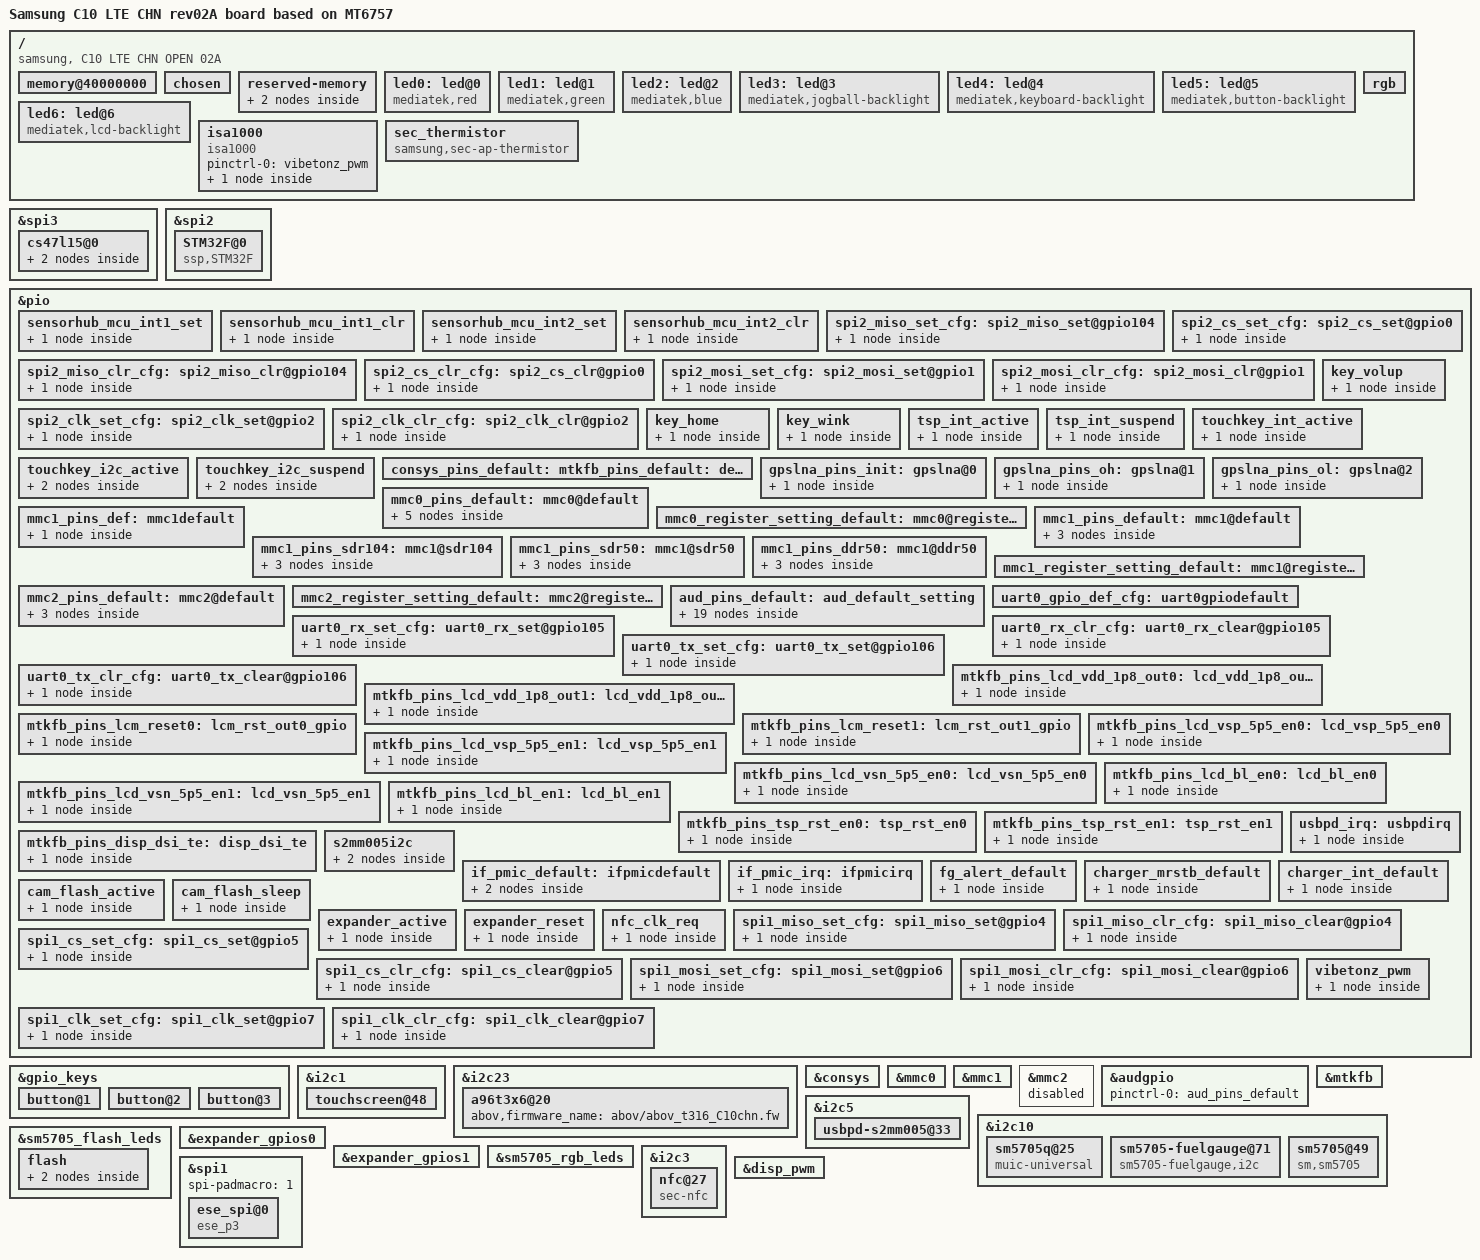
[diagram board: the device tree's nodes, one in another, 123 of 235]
/dts-v1/;

#include "mt6757.dtsi"
#include "mt6757_c10lte_chn_open_gpio_05.dtsi"
#include "mt6757_c10lte_fingerprint-sensor_00.dtsi"
#include <dt-bindings/input/input.h>
#include "battery_data_c10y17lte_common.dtsi"
#include "modem-MTK6757ap-pdata.dtsi"
#include "mt6757_camera_sensor_c10lte_chn_open_00.dtsi"
#include "mt6757_c10lte_sound.dtsi"
#include "mt6757_input_c10_common.dtsi"
#include "mtk-dsi-panel_s6e3fa3_ams549ku2x.dtsi"

/ {
	model = "Samsung C10 LTE CHN rev02A board based on MT6757";
	model_info-chip = <6757>;
	model_info-platform = "android";
	model_info-subtype = "mediatek";
	model_info-hw_rev = <5>;
	model_info-hw_rev_end = <5>;
	compatible = "samsung, C10 LTE CHN OPEN 02A", "mediatek,MT6757";

	memory@40000000 {
		device_type = "memory";
		reg = <0 0x40000000 0 0x1e605000>,
		      <1 0x00000000 0 0x20000000>;
	};

	/* chosen */
	chosen {
		bootargs = "console=tty0 console=ttyMT0,921600n1 root=/dev/ram initrd=0x45000000,
		0x1000000 loglevel=8 androidboot.selinux=permissive androidboot.hardware=mt6757";
		/* fpga may has no lk, we need to specify display info here */
		/* fb buffer is reserved using this dts by memory node above */
		atag,videolfb-fb_base_h = <0x0>;
		atag,videolfb-fb_base_l = <0x5e605000>;
		atag,videolfb-islcmfound = <1>;
		/* because no lk, so lcm is not inited */
		atag,videolfb-islcm_inited = <0>;
		atag,videolfb-fps= <6000>;
		atag,videolfb-vramSize= <0x017bb000>;
		atag,videolfb-dal_en= <0>;
		atag,videolfb-lcmname= "nt35695_fhd_dsi_cmd_truly_nt50358_drv";
	};

	reserved-memory {
		#address-cells = <2>;
		#size-cells = <2>;
		ranges;

		zone-movable-cma-memory {
			compatible = "mediatek,zone_movable_cma";
			size = <0 0x10000000>;
			/* 256MB alignment */
			alignment = <0 0x10000000>;
			alloc-ranges = <0 0xc0000000 1 0x00000000>;
		};

		dedicate-tui-memory {
			compatible = "mediatek,memory-tui";
			size = <0 0x2000000>;
			alignment = <0 0x400000>;
			alloc-ranges = <0 0x40000000 0 0x80000000>;
		};
	};

	led0:led@0 {
		compatible = "mediatek,red";
		led_mode = <0>;
		data = <1>;
		pwm_config = <0 0 0 0 0>;
	};
	led1:led@1 {
		compatible = "mediatek,green";
		led_mode = <0>;
		data = <1>;
		pwm_config = <0 0 0 0 0>;
	};
	led2:led@2 {
		compatible = "mediatek,blue";
		led_mode = <0>;
		data = <1>;
		pwm_config = <0 0 0 0 0>;
	};
	led3:led@3 {
		compatible = "mediatek,jogball-backlight";
		led_mode = <0>;
		data = <1>;
		pwm_config = <0 0 0 0 0>;
	};
	led4:led@4 {
		compatible = "mediatek,keyboard-backlight";
		led_mode = <0>;
		data = <1>;
		pwm_config = <0 0 0 0 0>;
	};
	led5:led@5 {
		compatible = "mediatek,button-backlight";
		led_mode = <0>;
		data = <1>;
		pwm_config = <0 0 0 0 0>;
	};
	led6:led@6 {
		compatible = "mediatek,lcd-backlight";
		led_mode = <4>;
		data = <1>;
		pwm_config = <3 0 0 0 0>;
	};

	/* VIBRATOR */
	isa1000:isa1000 {
		compatible = "isa1000";
	};

	/* start svc leds */
	rgb {
		device_type = <0>;
		rgb-name = "led_b", "led_g", "led_r";
		rgb-channel = <1 2 3>;

		normal_powermode_current = <255>;
		low_powermode_current = <51>;
		br_ratio_r = <26>;
		br_ratio_g = <5>;
		br_ratio_b = <49>;

		normal_powermode_current_bk = <255>;
		low_powermode_current_bk = <51>;
		br_ratio_r_bk = <26>;
		br_ratio_g_bk = <5>;
		br_ratio_b_bk = <49>;

		normal_powermode_current_gd = <255>;
		low_powermode_current_gd = <51>;
		br_ratio_r_gd = <11>;
		br_ratio_g_gd = <3>;
		br_ratio_b_gd = <55>;

		normal_powermode_current_wt = <255>;
		low_powermode_current_wt = <51>;
		br_ratio_r_wt = <18>;
		br_ratio_g_wt = <4>;
		br_ratio_b_wt = <42>;
	};
	/* end svc leds */

	sec_thermistor {
		compatible = "samsung,sec-ap-thermistor";
		status = "okay";
		adc_channel = <0>;
		adc_array = <65 88 109 133 163 199 240
                    254 262 270 280 288 300 316 325 338 367
                    380 399 412 426 439 452 464 489 521 547
                    560 570 578 616 643 675 708 735 763 790
                    952 1151 1389 1602 1934 2215 2664 2951 3428 3967
                    4502 4986>;

 		temp_array = <900 850 800 750 700 650 600        
					590 580 570 560 550 540 530 520 510 500
					490 480 470 460 450 440 430 420 410 400
					390 380 370 360 350 340 330 320 310 300
					250 200 150 100 50 0 (-50) (-100) (-150) (-200)
					(-250) (-300)>;
	};

	/delete-node/ accdet@;
};

/* audio device for each revision */
&spi3 {
	cs47l15@0 {
		cirrus,accdet {
			acc@1 {
				cirrus,micd-configs = <1 0 0xf 0 0>;
			};
		};
	};
};

/* Sensor Hub Start*/
&spi2 {
        #address-cells = <1>;
        #size-cells = <0>;
        status = "okay";

	STM32F@0 {
		compatible = "ssp,STM32F";
		reg = <0x00>;
		spi-max-frequency = <8000000>;

		interrupt-parent = <&eintc>;
		interrupts = <9 IRQ_TYPE_EDGE_FALLING>;

		pinctrl-names = "spi2_miso_set_cfg",
		"spi2_miso_clr_cfg",
		"spi2_cs_set_cfg",
		"spi2_cs_clr_cfg",
		"spi2_mosi_set_cfg",
		"spi2_mosi_clr_cfg",
		"spi2_clk_set_cfg",
		"spi2_clk_clr_cfg",
		"sensorhub_mcu_int1_set",
		"sensorhub_mcu_int1_clr",
		"sensorhub_mcu_int2_set",
		"sensorhub_mcu_int2_clr";
		pinctrl-0 = <&spi2_miso_set_cfg>;
		pinctrl-1 = <&spi2_miso_clr_cfg>;
		pinctrl-2 = <&spi2_cs_set_cfg>;
		pinctrl-3 = <&spi2_cs_clr_cfg>;
		pinctrl-4 = <&spi2_mosi_set_cfg>;
		pinctrl-5 = <&spi2_mosi_clr_cfg>;
		pinctrl-6 = <&spi2_clk_set_cfg>;
		pinctrl-7 = <&spi2_clk_clr_cfg>;

		pinctrl-8 = <&sensorhub_mcu_int1_set>;
		pinctrl-9 = <&sensorhub_mcu_int1_clr>;
		pinctrl-10 = <&sensorhub_mcu_int2_set>;
		pinctrl-11 = <&sensorhub_mcu_int2_clr>;

		gpio-controller;
		#gpio-cells = <2>;
		ssp,mcu_int1-gpio = <&pio 9 0>;
		ssp,mcu_int2-gpio = <&pio 115 0>;
		ssp,ap_int-gpio = <&expander_gpios1 4 0>;
		ssp,rst-gpio = <&expander_gpios1 3 0>;
		ssp,boot0-gpio = <&expander_gpios0 4 0>;
		ssp,acc-position = <3>;
		ssp,mag-position = <7>;
		ssp,prox-hi_thresh = <55>;
		ssp,prox-low_thresh = <40>;
		ssp,prox-detect_hi_thresh = <250>;
		ssp,prox-detect_low_thresh = <130>;
		ssp,mag-array = /bits/ 8 <0 0 0 0 0 0 0 0 0 0
					0 0 0 0 0 0 0 0 0 0
					0 0 0 0 0 0 0>;
		ssp,mag-type = <1>;
		ssp,acc-type = <1>;
		ssp,pressure-type = <1>;
		ssp,prox-type = <2>;
		/*ssp-sns-combination = <0>; where this is used*/
		/*ssp-ap-rev = <1>;*/
		
	};
};

&pio{
	sensorhub_mcu_int1_set: sensorhub_mcu_int1_set {
		pins_cmd_dat {
			pins = <PINMUX_GPIO9__FUNC_GPIO9>;
			slew-rate = <0>;	/* in */
			bias-disable;	/* no pull*/
		};
	};
	sensorhub_mcu_int1_clr: sensorhub_mcu_int1_clr {
		pins_cmd_dat {
			pins = <PINMUX_GPIO9__FUNC_GPIO9>;
			slew-rate = <0>;	/* in */
			bias-disable;	/* no pull*/
		};
	};
	sensorhub_mcu_int2_set: sensorhub_mcu_int2_set {
		pins_cmd_dat {
			pins = <PINMUX_GPIO115__FUNC_GPIO115>;
			slew-rate = <0>;	/* in */
			bias-disable;	/* no pull*/
		};
	};
	sensorhub_mcu_int2_clr: sensorhub_mcu_int2_clr {
		pins_cmd_dat {
			pins = <PINMUX_GPIO115__FUNC_GPIO115>;
			slew-rate = <0>;	/* in */
			bias-disable;	/* no pull*/
		};
	};  

	/* SPI2 GPIO SETTING */
	spi2_miso_set_cfg: spi2_miso_set@gpio104 {
		pins_cmd_dat {
			pins = <PINMUX_GPIO104__FUNC_SPI2_MI>;
		};
	};
	spi2_miso_clr_cfg: spi2_miso_clr@gpio104 {
		pins_cmd_dat {
			pins = <PINMUX_GPIO104__FUNC_GPIO104>;
			slew-rate = <0>;
			bias-pull-down = <00>;
		};
	};
	
	spi2_cs_set_cfg: spi2_cs_set@gpio0 {
		pins_cmd_dat {
			pins = <PINMUX_GPIO0__FUNC_SPI2_CSB>;
		};
	};
	spi2_cs_clr_cfg: spi2_cs_clr@gpio0 {
		pins_cmd_dat {
			pins = <PINMUX_GPIO0__FUNC_GPIO0>;
			slew-rate = <1>;
			output-low;
			bias-disable;
		};
	};
	
	spi2_mosi_set_cfg: spi2_mosi_set@gpio1 {
		pins_cmd_dat {
			pins = <PINMUX_GPIO1__FUNC_SPI2_MO>;
		};
	};
	spi2_mosi_clr_cfg: spi2_mosi_clr@gpio1 {
		pins_cmd_dat {
			pins = <PINMUX_GPIO1__FUNC_GPIO1>;
			slew-rate = <1>;
			output-low;
			bias-disable;
		};
	};
	
	spi2_clk_set_cfg: spi2_clk_set@gpio2 {
		pins_cmd_dat {
			pins = <PINMUX_GPIO2__FUNC_SPI2_CLK>;
		};
	};
	spi2_clk_clr_cfg: spi2_clk_clr@gpio2 {
		pins_cmd_dat {
			pins = <PINMUX_GPIO2__FUNC_GPIO2>;
			slew-rate = <1>;
			output-low;
			bias-disable;
		};
	};
};
/* Sensor Hub End*/

/* gpio keys */
&gpio_keys {
	status = "okay";
	button@1 {
		status = "okay";
	};
	button@2 {
		status = "okay";
	};
	button@3 {
		status = "okay";
	};
};

&pio {
	key_volup: key_volup {
		pins_cmd_dat {
			pins = <PINMUX_GPIO43__FUNC_GPIO43>;
			slew-rate = <0>;
			bias-pull-up = <00>;
		};
	};
	key_home: key_home{
		pins_cmd_dat {
			pins = <PINMUX_GPIO42__FUNC_GPIO42>;
			slew-rate = <0>;
			bias-pull-up = <00>;
		};
	};
	key_wink: key_wink{
		pins_cmd_dat {
			pins = <PINMUX_GPIO21__FUNC_GPIO21>;
			slew-rate = <0>;
			bias-pull-up = <00>;
		};
	};
};

/* TOUCH start */
&i2c1 {
	status = "okay";
	touchscreen@48 {
		status = "okay";
	};
};

&pio {
	tsp_int_active: tsp_int_active {
		pins_cmd_dat {
			pins = <PINMUX_GPIO3__FUNC_GPIO3>;	/*tsp eint pin*/
			slew-rate = <0>;
			bias-disable;
		};
	};
	tsp_int_suspend: tsp_int_suspend {
		pins_cmd_dat {
			pins = <PINMUX_GPIO3__FUNC_GPIO3>;	/*tsp eint pin*/
			slew-rate = <0>;
			bias-pull-down = <11>;
		};
	};
};
/* TOUCH end */

/* TOUCH KEY start */
&i2c23 {
	status = "okay";
	a96t3x6@20{
		abov,firmware_name = "abov/abov_t316_C10chn.fw";
		status = "okay";
	};
};

&pio {
	touchkey_int_active: touchkey_int_active {
		pins_cmd_dat {
			pins = <PINMUX_GPIO11__FUNC_GPIO11>;	/*touchkey eint pin*/
			slew-rate = <0>;
			bias-disable;
		};
	};

	touchkey_i2c_active: touchkey_i2c_active {
		pins_cmd_dat1 {
			pins = <PINMUX_GPIO190__FUNC_GPIO190>;	/*touchkey i2c pin*/
			slew-rate = <0>;
			bias-disable;
		};
		pins_cmd_dat2 {
			pins = <PINMUX_GPIO191__FUNC_GPIO191>;	/*touchkey i2c pin*/
			slew-rate = <0>;
			bias-disable;
		};
	};
	touchkey_i2c_suspend: touchkey_i2c_suspend {
		pins_cmd_dat1 {
			pins = <PINMUX_GPIO190__FUNC_GPIO190>;	/*touchkey i2c pin*/
			slew-rate = <0>;
			bias-disable;
		};
		pins_cmd_dat2 {
			pins = <PINMUX_GPIO191__FUNC_GPIO191>;	/*touchkey i2c pin*/
			slew-rate = <0>;
			bias-disable;
		};
	};
};

/* TOUCH KEY end */


/* CONSYS GPIO standardization */
&pio {
	consys_pins_default: default {
	};
	gpslna_pins_init: gpslna@0 {
		pins_cmd_dat {
			pins = <PINMUX_GPIO114__FUNC_GPIO114>;
			slew-rate = <0>;
			bias-disable;
			output-low;
		};
	};
	gpslna_pins_oh: gpslna@1 {
		pins_cmd_dat {
			pins = <PINMUX_GPIO114__FUNC_GPIO114>;
			slew-rate = <1>;
			output-high;
		};
	};
	gpslna_pins_ol: gpslna@2 {
		pins_cmd_dat {
			pins = <PINMUX_GPIO114__FUNC_GPIO114>;
			slew-rate = <1>;
			output-low;
		};
	};
};
&consys {
	pinctrl-names = "default", "gps_lna_state_init", "gps_lna_state_oh", "gps_lna_state_ol";
	pinctrl-0 = <&consys_pins_default>;
	pinctrl-1 = <&gpslna_pins_init>;
	pinctrl-2 = <&gpslna_pins_oh>;
	pinctrl-3 = <&gpslna_pins_ol>;
	status = "okay";
};
/* CONSYS end */

/**********************************************
 *MT6757 MSDC DTSI File
********************************************/

&mmc0 {
	clk_src = /bits/ 8 <MSDC50_CLKSRC_400MHZ>;
	bus-width = <8>;
	max-frequency = <200000000>;
	cap-mmc-highspeed;
	msdc-sys-suspend;
        emmc_power_ao;
	mmc-ddr-1_8v;
	mmc-hs200-1_8v;
	mmc-hs400-1_8v;
	non-removable;
	pinctl = <&mmc0_pins_default>;
	register_setting = <&mmc0_register_setting_default>;
	host_function = /bits/ 8 <MSDC_EMMC>;
	bootable;
	status = "okay";
	vmmc-supply = <&mt_pmic_vemc_ldo_reg>;
};

&mmc1 {
	clk_src = /bits/ 8 <MSDC30_CLKSRC_200MHZ>;
	bus-width = <4>;
	max-frequency = <200000000>;
	msdc-sys-suspend;
	cap-sd-highspeed;
	sd-uhs-sdr12;
	sd-uhs-sdr25;
	sd-uhs-sdr50;
	sd-uhs-sdr104;
	sd-uhs-ddr50;
	pinctl = <&mmc1_pins_default>;
	pinctl_sdr104 = <&mmc1_pins_sdr104>;
	pinctl_sdr50 = <&mmc1_pins_sdr50>;
	pinctl_ddr50 = <&mmc1_pins_ddr50>;
	register_setting = <&mmc1_register_setting_default>;
	host_function = /bits/ 8 <MSDC_SD>;
	cd_level = /bits/ 8 <MSDC_CD_LOW>;
        cd-gpios = <&pio 23 GPIO_ACTIVE_LOW>;
        pinctrl-names = "default";
        pinctrl-0 = <&mmc1_pins_def>;
	status = "okay";
	vmmc-supply = <&mt_pmic_vmch_ldo_reg>;
	vqmmc-supply = <&mt_pmic_vmc_ldo_reg>;
};

&mmc2 {
	clk_src = /bits/ 8 <MSDC30_CLKSRC_200MHZ>;
	bus-width = <4>;
	max-frequency = <200000000>;
	cap-sd-highspeed;
	sd-uhs-sdr12;
	sd-uhs-sdr25;
	sd-uhs-sdr50;
	sd-uhs-sdr104;
	sd-uhs-ddr50;
	keep-power-in-suspend;
	non-removable;
	pinctl = <&mmc2_pins_default>;
	register_setting = <&mmc2_register_setting_default>;
	host_function = /bits/ 8 <MSDC_SDIO>;
	status = "disable";
};

&pio {
	mmc0_pins_default: mmc0@default {
		pins_cmd {
			drive-strength = /bits/ 8 <3>;
		};
		pins_dat {
			drive-strength = /bits/ 8 <3>;
		};
		pins_clk {
			drive-strength = /bits/ 8 <3>;
		};
		pins_rst {
			drive-strength = /bits/ 8 <3>;
		};
		pins_ds {
			drive-strength = /bits/ 8 <1>;
		};
	};

	mmc0_register_setting_default: mmc0@register_default {
		datrddly      = /bits/ 8 <0 0 0 0 0 0 0 0>;
		datwrddly      = /bits/ 8 <0>;
		cmdrrddly      = /bits/ 8 <0>;
		cmdrddly       = /bits/ 8 <0>;
		cmd_edge = /bits/ 8 <MSDC_SMPL_FALLING>;
		rdata_edge = /bits/ 8 <MSDC_SMPL_FALLING>;
		wdata_edge = /bits/ 8 <MSDC_SMPL_FALLING>;
	};

        mmc1_pins_def: mmc1default {
        pins_cmd_dat {
                pins = <PINMUX_GPIO23__FUNC_GPIO23>;
                bias-disable;
                };
        };

	mmc1_pins_default: mmc1@default {
		pins_cmd {
			drive-strength = /bits/ 8 <3>;
		};
		pins_dat {
			drive-strength = /bits/ 8 <3>;
		};
		pins_clk {
			drive-strength = /bits/ 8 <4>;
		};
	};

	mmc1_pins_sdr104: mmc1@sdr104 {
		pins_cmd {
			drive-strength = /bits/ 8 <3>;
		};
		pins_dat {
			drive-strength = /bits/ 8 <3>;
		};
		pins_clk {
			drive-strength = /bits/ 8 <3>;
		};
	};

	mmc1_pins_sdr50: mmc1@sdr50 {
		pins_cmd {
			drive-strength = /bits/ 8 <3>;
		};
		pins_dat {
			drive-strength = /bits/ 8 <3>;
		};
		pins_clk {
			drive-strength = /bits/ 8 <3>;
		};
	};

	mmc1_pins_ddr50: mmc1@ddr50 {
		pins_cmd {
			drive-strength = /bits/ 8 <3>;
		};
		pins_dat {
			drive-strength = /bits/ 8 <3>;
		};
		pins_clk {
			drive-strength = /bits/ 8 <3>;
		};
	};

	mmc1_register_setting_default: mmc1@register_default {
		datrddly       = /bits/ 8 <0 0 0 0 0 0 0 0>;
		datwrddly      = /bits/ 8 <0>;
		cmdrrddly      = /bits/ 8 <0>;
		cmdrddly       = /bits/ 8 <0>;
		cmd_edge = /bits/ 8 <MSDC_SMPL_RISING>;
		rdata_edge = /bits/ 8 <MSDC_SMPL_RISING>;
		wdata_edge = /bits/ 8 <MSDC_SMPL_RISING>;
	};

	mmc2_pins_default: mmc2@default {
		pins_cmd {
			drive-strength = /bits/ 8 <3>;
		};
		pins_dat {
			drive-strength = /bits/ 8 <3>;
		};
		pins_clk {
			drive-strength = /bits/ 8 <3>;
		};
	};

	mmc2_register_setting_default: mmc2@register_default {
		datrddly       = /bits/ 8 <0 0 0 0 0 0 0 0>;
		datwrddly      = /bits/ 8 <0>;
		cmdrrddly      = /bits/ 8 <0>;
		cmdrddly       = /bits/ 8 <0>;
		cmd_edge = /bits/ 8 <MSDC_SMPL_FALLING>;
		rdata_edge = /bits/ 8 <MSDC_SMPL_FALLING>;
		wdata_edge = /bits/ 8 <MSDC_SMPL_FALLING>;
	};
};
/* MMC end*/

/* AUDIO GPIO standardization */
&audgpio {
	pinctrl-names = "default";
	pinctrl-0 = <&aud_pins_default>;
	status = "okay";
};

&pio {
	aud_pins_default: aud_default_setting {
		pins_cmd0_dat {
			pins = <PINMUX_GPIO107__FUNC_SPI3_CSB>;
		};
		pins_cmd1_dat{
			pins = <PINMUX_GPIO108__FUNC_SPI3_MI>;
		};
		pins_cmd2_dat{
			pins = <PINMUX_GPIO110__FUNC_SPI3_CLK>;
		};
		pins_cmd3_dat{
			pins = <PINMUX_GPIO111__FUNC_SPI3_MO>;
		};
		pins_cmd4_dat {
			pins = <PINMUX_GPIO16__FUNC_I2S0_DI>;
			bias-disable;
		};
		pins_cmd5_dat {
			pins = <PINMUX_GPIO25__FUNC_I2S3_MCK>;
			bias-disable;
		};
		pins_cmd6_dat {
			pins = <PINMUX_GPIO26__FUNC_I2S3_BCK>;
			bias-disable;
		};
		pins_cmd7_dat {
			pins = <PINMUX_GPIO27__FUNC_I2S3_LRCK>;
			bias-disable;
		};
		pins_cmd8_dat {
			pins = <PINMUX_GPIO28__FUNC_I2S3_DO>;
			bias-disable;
		};
		pins_cmd9_dat {
			pins = <PINMUX_GPIO75__FUNC_I2S2_DI>;
			bias-disable;
		};
		pins_cmd10_dat {
			pins = <PINMUX_GPIO149__FUNC_I2S1_BCK>;
		};
		pins_cmd11_dat {
			pins = <PINMUX_GPIO150__FUNC_I2S1_LRCK>;
		};
		pins_cmd12_dat {
			pins = <PINMUX_GPIO151__FUNC_I2S1_DO>;
		};
		pins_cmd13_dat {
			pins = <PINMUX_GPIO84__FUNC_GPIO84>;
			slew-rate = <0>;
			bias-pull-up = <00>;
		};
		pins_cmd14_dat {
			pins = <PINMUX_GPIO13__FUNC_GPIO13>;
			slew-rate = <0>;
			bias-pull-up = <00>;
		};
		pins_cmd15_dat{
			pins = <PINMUX_GPIO19__FUNC_SPI5_MO>;
		};
		pins_cmd16_dat{
			pins = <PINMUX_GPIO20__FUNC_SPI5_CLK>;
		};
		pins_cmd17_dat{
			pins = <PINMUX_GPIO45__FUNC_SPI5_MI>;
		};
		pins_cmd18_dat{
			pins = <PINMUX_GPIO46__FUNC_SPI5_CSB>;
		};
	};
};
/* AUDIO end */

&mmc1 {
	status = "okay";
};

/* UART GPIO */
/*
*&apuart0 {
*	pinctrl-names = "uart0_gpio_default",
*			"uart0_rx_set",
*			"uart0_rx_clear",
*			"uart0_tx_set",
*			"uart0_tx_clear";
*	pinctrl-0 = <&uart0_gpio_def_cfg>;
*	pinctrl-1 = <&uart0_rx_set_cfg>;
*	pinctrl-2 = <&uart0_rx_clr_cfg>;
*	pinctrl-3 = <&uart0_tx_set_cfg>;
*	pinctrl-4 = <&uart0_tx_clr_cfg>;
*	status = "okay";
*};
*/
&pio {
	/* UART GPIO Settings - Start */
	/* UART0: rx set, rx clear, tx clear, tx clear*/
	uart0_gpio_def_cfg:uart0gpiodefault {

	};
	uart0_rx_set_cfg:uart0_rx_set@gpio105 {
		pins_cmd_dat {
			pins = <PINMUX_GPIO105__FUNC_URXD0>;
		};
	};
	uart0_rx_clr_cfg:uart0_rx_clear@gpio105  {
		pins_cmd_dat {
			pins = <PINMUX_GPIO105__FUNC_GPIO105>;
			slew-rate = <1>;
			output-high;
		};
	};
	uart0_tx_set_cfg:uart0_tx_set@gpio106  {
		pins_cmd_dat {
			pins = <PINMUX_GPIO106__FUNC_UTXD0>;
		};
	};
	uart0_tx_clr_cfg:uart0_tx_clear@gpio106  {
		pins_cmd_dat {
			pins = <PINMUX_GPIO106__FUNC_GPIO106>;
			slew-rate = <1>;
			output-high;
		};
	};
};/* UART GPIO end */

/* DISPSYS GPIO standardization */
&pio {

	mtkfb_pins_lcd_vdd_1p8_out0: lcd_vdd_1p8_out0 {
		pins_cmd_dat {
			pins = <PINMUX_GPIO22__FUNC_GPIO22>;
			slew-rate = <1>;
			output-low;
		};
	};

	mtkfb_pins_lcd_vdd_1p8_out1: lcd_vdd_1p8_out1 {
		pins_cmd_dat {
			pins = <PINMUX_GPIO22__FUNC_GPIO22>;
			slew-rate = <1>;
			output-high;
		};
	};

	mtkfb_pins_lcm_reset0: lcm_rst_out0_gpio {
		pins_cmd_dat {
			pins = <PINMUX_GPIO158__FUNC_GPIO158>;
			slew-rate = <1>;
			output-low;
		};
	};

	mtkfb_pins_lcm_reset1: lcm_rst_out1_gpio {
		pins_cmd_dat {
			pins = <PINMUX_GPIO158__FUNC_GPIO158>;
			slew-rate = <1>;
			output-high;
		};
	};

	mtkfb_pins_lcd_vsp_5p5_en0: lcd_vsp_5p5_en0 {
		pins_cmd_dat {
			pins = <PINMUX_GPIO20__FUNC_GPIO20>;
			slew-rate = <1>;
			output-low;
		};
	};

	mtkfb_pins_lcd_vsp_5p5_en1: lcd_vsp_5p5_en1 {
		pins_cmd_dat {
			pins = <PINMUX_GPIO20__FUNC_GPIO20>;
			slew-rate = <1>;
			output-high;
		};
	};

	mtkfb_pins_lcd_vsn_5p5_en0: lcd_vsn_5p5_en0 {
		pins_cmd_dat {
			pins = <PINMUX_GPIO19__FUNC_GPIO19>;
			slew-rate = <1>;
			output-low;
		};
	};

	mtkfb_pins_lcd_vsn_5p5_en1: lcd_vsn_5p5_en1 {
		pins_cmd_dat {
			pins = <PINMUX_GPIO19__FUNC_GPIO19>;
			slew-rate = <1>;
			output-high;
		};
	};

	mtkfb_pins_lcd_bl_en0: lcd_bl_en0 {
		pins_cmd_dat {
			pins = <PINMUX_GPIO21__FUNC_GPIO21>;
			slew-rate = <1>;
			output-low;
		};
	};

	mtkfb_pins_lcd_bl_en1: lcd_bl_en1 {
		pins_cmd_dat {
			pins = <PINMUX_GPIO21__FUNC_GPIO21>;
			slew-rate = <1>;
			output-high;
		};
	};

	mtkfb_pins_tsp_rst_en0: tsp_rst_en0 {
		pins_cmd_dat {
			pins = <PINMUX_GPIO18__FUNC_GPIO18>;
			slew-rate = <1>;
			output-low;
		};
	};

	mtkfb_pins_tsp_rst_en1: tsp_rst_en1 {
		pins_cmd_dat {
			pins = <PINMUX_GPIO18__FUNC_GPIO18>;
			slew-rate = <1>;
			output-high;
		};
	};

	mtkfb_pins_disp_dsi_te: disp_dsi_te {
		pins_cmd_dat {
			pins = <PINMUX_GPIO44__FUNC_DSI_TE>;
		};
	};

	mtkfb_pins_default: default {
	};

};

&mtkfb {
	pinctrl-names = "default", "lcd_vdd_1p8_out0", "lcd_vdd_1p8_out1", "lcm_rst_out0_gpio",
	"lcm_rst_out1_gpio", "lcd_vsp_5p5_en0", "lcd_vsp_5p5_en1", "lcd_vsn_5p5_en0", "lcd_vsn_5p5_en1",
	"lcd_bl_en0", "lcd_bl_en1", "tsp_rst_en0", "tsp_rst_en1", "disp_dsi_te";

	pinctrl-0 = <&mtkfb_pins_default>;
	pinctrl-1 = <&mtkfb_pins_lcd_vdd_1p8_out0>;
	pinctrl-2 = <&mtkfb_pins_lcd_vdd_1p8_out1>;
	pinctrl-3 = <&mtkfb_pins_lcm_reset0>;
	pinctrl-4 = <&mtkfb_pins_lcm_reset1>;
	pinctrl-5 = <&mtkfb_pins_lcd_vsp_5p5_en0>;
	pinctrl-6 = <&mtkfb_pins_lcd_vsp_5p5_en1>;
	pinctrl-7 = <&mtkfb_pins_lcd_vsn_5p5_en0>;
	pinctrl-8 = <&mtkfb_pins_lcd_vsn_5p5_en1>;
	pinctrl-9 = <&mtkfb_pins_lcd_bl_en0>;
	pinctrl-10 = <&mtkfb_pins_lcd_bl_en1>;
	pinctrl-11 = <&mtkfb_pins_tsp_rst_en0>;
	pinctrl-12 = <&mtkfb_pins_tsp_rst_en1>;
	pinctrl-13 = <&mtkfb_pins_disp_dsi_te>;
	status = "okay";
};/* DISPSYS GPIO standardization end */

/* CCIC */
&i2c5 {
	#address-cells = <1>;
	#size-cells = <0>;
	status = "okay";


	usbpd-s2mm005@33 {
		pinctrl-names = "default";
		pinctrl-0 = <&usbpd_irq &s2mm005i2c>;
		interrupt-parent = <&eintc>;
		interrupts = <116 IRQ_TYPE_EDGE_FALLING>;
		usbpd,usbpd_int = <&pio 116 0>;
		usbpd,s2mm005_sda = <&pio 48 0>;
		usbpd,s2mm005_scl = <&pio 47 0>;

	};
};

&pio {

	usbpd_irq: usbpdirq {

		pins_cmd_dat {
			pins = <PINMUX_GPIO116__FUNC_GPIO116>;
			slew-rate = <0>;
			bias-disable;
		};

	};

	s2mm005i2c: s2mm005i2c {

		pins_cmd_dat1 {
			pins = <PINMUX_GPIO48__FUNC_SDA_APPM>;
			slew-rate = <0>;
			bias-disable;
		};
		pins_cmd_dat2 {
			pins = <PINMUX_GPIO47__FUNC_SCL_APPM>;
			slew-rate = <0>;
			bias-disable;
		};
	};

};
/* CCIC END */
/* IF-PMIC configurations */
&i2c10 {
	status = "okay";
	sm5705q@25 {
		compatible = "muic-universal";
		reg = <0x25>;
		interrupt-parent = <&eintc>;
		interrupts = <12 IRQ_TYPE_EDGE_FALLING>;
		pinctrl-names = "default";
		pinctrl-0 = <&if_pmic_default &if_pmic_irq>;

		muic-universal,chip_name = "sm,sm5705";
		muic-universal,irq-gpio = <&pio 12 GPIO_ACTIVE_LOW>;
		muic,sm5705_switch_gpio = <&expander_gpios0 13 GPIO_ACTIVE_HIGH>;	// U4000, P1_5
		muic,max-afc-support-volt = <4>;
		muic,max-afc-support-cur = <8>;
		status = "okay";
	};

	sm5705-fuelgauge@71 {
		compatible = "sm5705-fuelgauge,i2c";
		reg = <0x71>;
		interrupt-parent = <&eintc>;
		pinctrl-names = "fg_alrt_default", "fg_default";
		pinctrl-0 = <&fg_alert_default &if_pmic_default>;
		fuelgauge,irqf = "IRQF_TRIGGER_FALLING + IRQF_ONESHOT + IRQF_NO_SUSPEND";
		fuelgauge,fuel_int = <&pio 85 0>;
		fuelgauge,fuel_alert_soc = <1>;
		fuelgauge,capacity_max = <1000>;
		fuelgauge,capacity_max_margin = <70>;
		fuelgauge,capacity_min = <0>;
		fuelgauge,capacity_calculation_type = <0x1F>;
		fuelgauge,capacity_full = <3000>;
	};

	sm5705@49 {
		compatible = "sm,sm5705";
		reg = <0x49>;
		interrupt-parent = <&eintc>;
		sm5705,irq-gpio = <&pio 8 0>;
		pinctrl-names = "mrstb_deault", "chg_ing_default";
		pinctrl-0 = <&charger_mrstb_default &charger_int_default>;
		sm5705,mrstb-gpio = <&expander_gpios1 9 0>;
	};
};

&pio {
	if_pmic_default: ifpmicdefault {
		pins_cmd_dat1 {
			pins = <PINMUX_GPIO22__FUNC_GPIO22>;
			slew-rate = <0>;
			bias-disable;
		};
		pins_cmd_dat2 {
			pins = <PINMUX_GPIO15__FUNC_GPIO15>;
			slew-rate = <0>;
			bias-disable;
		};
	};

	if_pmic_irq: ifpmicirq {
		pins_cmd_dat {
			pins = <PINMUX_GPIO12__FUNC_GPIO12>;
			slew-rate = <0>;
			bias-disable;
		};
	};

	fg_alert_default: fg_alert_default {
		pins_cmd_dat {
			pins = <PINMUX_GPIO85__FUNC_GPIO85>;
			slew-rate = <0>;
			bias-disable;
		};
	};

	charger_mrstb_default: charger_mrstb_default {
		pins_cmd_dat {
			pins = <PINMUX_GPIO12__FUNC_GPIO12>;
			slew-rate = <0>;
			bias-disable;
		};
	};

	charger_int_default: charger_int_default {
		pins_cmd_dat {
			pins = <PINMUX_GPIO8__FUNC_GPIO8>;
			slew-rate = <0>;
			bias-disable;
		};
	};
};
/* IF-PMIC end */

&sm5705_flash_leds{

	 flash{
			status = "okay";
			
			led1 {
				ledname = "leds-sm5705-fled0";
				id = <0>;
				flash-mode-current-mA = <1000>;
				torch-mode-current-mA = <150>;
				used-gpio-control = <1>;			
				flash-en-gpio = <&pio 88 0x00>;			
				torch-en-gpio = <&expander_gpios1 11 0>;
			};

			led2 {
				ledname = "leds-sm5705-fled1";
				id = <1>;
				flash-mode-current-mA = <1000>;
				torch-mode-current-mA = <150>;
				used-gpio-control = <1>;			
				flash-en-gpio = <&pio 55 0x00>;			
				torch-en-gpio = <&expander_gpios1 13 0>;			
			};
};
};


&pio {
		cam_flash_active: cam_flash_active {
			pins_cmd_dat {
				pins = <PINMUX_GPIO88__FUNC_GPIO88>;
				slew-rate = <1>; /*direction 0:in, 1:out*/
				bias-disable;
				output-high;
			};
		};
		cam_flash_sleep: cam_flash_sleep {
			pins_cmd_dat {
				pins = <PINMUX_GPIO88__FUNC_GPIO88>;
				slew-rate = <1>; /*direction 0:in, 1:out*/
				bias-disable;
				output-low;/*direction out used only. output_low or high*/
			};
		};
		
};


/* GPIO expander */
&expander_gpios0 {
		pinctrl-names = "default", "reset";
		pinctrl-0 = <&expander_active>;
		pinctrl-1 = <&expander_reset>;
		pcal6524,gpio_start = <200>;
		pcal6524,addr = <0>;
		pcal6524,ngpio = <24>;
		pcal6524,reset-gpio = <&pio 102 GPIO_ACTIVE_LOW>;
		pcal6524,support_initialize = <1>;
		/* config, 24 ~ 0, 1bit configure[1:input, 0:output]*/
		pcal6524,config = <0xFFFFFF>;    /* P2[11111111] P1[11111111] P0[11111111] */
		/* data_out, 24 ~ 0, 1bit configure[1:high, 0:low]*/
		pcal6524,data_out = <0x000000>;  /* P2[00000000] P1[00100000] P0[00000000] */
		/* pull_reg, 8 ~ 0, 2bit configure[00:no_pull, 01:pull_down, 10:pull_up, 11:not used] */
		pcal6524,pull_reg_p0 = <0x0000>; /* 00 00 00 00 / 00 00 00 00 */
		pcal6524,pull_reg_p1 = <0x0000>; /* 00 00 00 00 / 00 00 00 00 */
		pcal6524,pull_reg_p2 = <0x0000>; /* 00 00 00 00 / 00 00 00 00 */
};

&expander_gpios1 {
		pcal6524,gpio_start = <224>;
		pcal6524,addr = <1>;
		pcal6524,ngpio = <24>;
		pcal6524,reset-gpio = <&pio 102 GPIO_ACTIVE_LOW>;
		pcal6524,support_initialize = <1>;
		/* config, 24 ~ 0, 1bit configure[1:input, 0:output]*/
		pcal6524,config = <0xFFFFFF>;    /* P2[11111111] P1[11111111] P0[11111111] */
		/* data_out, 24 ~ 0, 1bit configure[1:high, 0:low]*/
		pcal6524,data_out = <0x000000>;  /* P2[00000000] P1[00100000] P0[00000000] */
		/* pull_reg, 8 ~ 0, 2bit configure[00:no_pull, 01:pull_down, 10:pull_up, 11:not used] */
		pcal6524,pull_reg_p0 = <0x0000>; /* 00 00 00 00 / 00 00 00 00 */
		pcal6524,pull_reg_p1 = <0x0000>; /* 00 00 00 00 / 00 00 00 00 */
		pcal6524,pull_reg_p2 = <0x0000>; /* 00 00 00 00 / 00 00 00 00 */
};

&pio {
	expander_active: expander_active {
		pins_cmd_dat {
			pins = <PINMUX_GPIO102__FUNC_GPIO102>;
			slew-rate = <1>;
			bias-disable;
			output-high;
		};
	};
	expander_reset: expander_reset {
		pins_cmd_dat {
			pins = <PINMUX_GPIO102__FUNC_GPIO102>;
			slew-rate = <1>;
			bias-disable;
			output-low;
		};
	};
};

&sm5705_rgb_leds {
	rgb,vdd-gpio =<&expander_gpios0 10 0>;

	normal_cur_bk = <255>;
	low_cur_bk = <10>;
	ratio_r_bk = <21>;
	ratio_g_bk = <12>;
	ratio_b_bk = <47>;
	ratio_r_low_bk = <74>;
	ratio_g_low_bk = <49>;
	ratio_b_low_bk = <85>;
/*
	normal_cur_gd = <255>;
	low_cur_gd = <10>;
	ratio_r_gd = <21>;
	ratio_g_gd = <12>;
	ratio_b_gd = <47>;
	ratio_r_low_gd = <74>;
	ratio_g_low_gd = <49>;
	ratio_b_low_gd = <85>;

	normal_cur_wt = <255>;
	low_cur_wt = <10>;
	ratio_r_wt = <21>;
	ratio_g_wt = <13>;
	ratio_b_wt = <47>;
	ratio_r_low_wt = <60>;
	ratio_g_low_wt = <40>;
	ratio_b_low_wt = <70>;

	normal_cur_bl = <255>;
	low_cur_bl = <10>;
	ratio_r_bl = <7>;
	ratio_g_bl = <5>;
	ratio_b_bl = <11>;
	ratio_r_low_bl = <20>;
	ratio_g_low_bl = <10>;
	ratio_b_low_bl = <20>;
*/
};

/* NFC start */
&i2c3 {
	address-cells = <1>;
	size-cells = <0>;
	status = "okay";
	nfc@27 {
		compatible = "sec-nfc";
		reg = <0x27>;
		interrupt-parent = <&eintc>;
		interrupts = <87 IRQ_TYPE_LEVEL_HIGH>;

		pinctrl-names = "default";
		pinctrl-0 = <&nfc_clk_req>;

		sec-nfc,firm-gpio = <&expander_gpios1 12 0>;
		sec-nfc,clk_req-gpio = <&pio 86 0>;
		sec-nfc,ven-gpio = <&expander_gpios0 12 0>;
		sec-nfc,irq-gpio = <&pio 87 0>;
		sec-nfc,pvdd-gpio = <&expander_gpios0 7 0>;
		sec-nfc,nfc_ap_clk;
	};
};
&pio {
	nfc_clk_req: nfc_clk_req {
		pins_cmd_dat {
			pins = <PINMUX_GPIO86__FUNC_GPIO86>;
			slew-rate = <0>;
			bias-pull-down = <00>;
		};
	};
};
/* NFC end */

/* eSE Start */
&spi1 {
	#address-cells = <1>;
	#size-cells = <0>;
	status = "okay";
	spi-padmacro = <1>; /* spi1_A :0, spi1_B :1 */

	ese_spi@0 {
		compatible = "ese_p3";
		reg = <0>;
		spi-max-frequency = <13000000>;
		pinctrl-names = "spi1_miso_set_cfg",
			"spi1_miso_clr_cfg",
			"spi1_cs_set_cfg",
			"spi1_cs_clr_cfg",
			"spi1_mosi_set_cfg",
			"spi1_mosi_clr_cfg",
			"spi1_clk_set_cfg",
			"spi1_clk_clr_cfg";
		/*spi pincntrl*/
		pinctrl-0 = <&spi1_miso_set_cfg>;
		pinctrl-1 = <&spi1_miso_clr_cfg>;
		pinctrl-2 = <&spi1_cs_set_cfg>;
		pinctrl-3 = <&spi1_cs_clr_cfg>;
		pinctrl-4 = <&spi1_mosi_set_cfg>;
		pinctrl-5 = <&spi1_mosi_clr_cfg>;
		pinctrl-6 = <&spi1_clk_set_cfg>;
		pinctrl-7 = <&spi1_clk_clr_cfg>;

		ese_p3,gpio_control;
		ese_p3,pvdd-gpio = <&expander_gpios0 6 0>;
	};
};
&pio {
	spi1_miso_set_cfg:spi1_miso_set@gpio4{
		pins_cmd_dat{
			pins = <PINMUX_GPIO4__FUNC_SPI1_B_MI>;
		};
	};
	spi1_miso_clr_cfg:spi1_miso_clear@gpio4{
		pins_cmd_dat{
			pins = <PINMUX_GPIO4__FUNC_GPIO4>;
			slew-rate = <0>;
			bias-pull-down = <00>;
		};
	};
	spi1_cs_set_cfg:spi1_cs_set@gpio5{
		pins_cmd_dat{
			pins = <PINMUX_GPIO5__FUNC_SPI1_B_CSB>;
		};
	};
	spi1_cs_clr_cfg:spi1_cs_clear@gpio5{
		pins_cmd_dat{
			pins = <PINMUX_GPIO5__FUNC_GPIO5>;
			slew-rate = <1>;
			output-low;
			bias-disable;
		};
	};
	spi1_mosi_set_cfg:spi1_mosi_set@gpio6{
		pins_cmd_dat{
			pins = <PINMUX_GPIO6__FUNC_SPI1_B_MO>;
		};
	};
	spi1_mosi_clr_cfg:spi1_mosi_clear@gpio6{
		pins_cmd_dat{
			pins = <PINMUX_GPIO6__FUNC_GPIO6>;
			slew-rate = <1>;
			output-low;
			bias-disable;
		};
	};
	spi1_clk_set_cfg:spi1_clk_set@gpio7{
		pins_cmd_dat{
			pins = <PINMUX_GPIO7__FUNC_SPI1_B_CLK>;
		};
	};
	spi1_clk_clr_cfg:spi1_clk_clear@gpio7{
		pins_cmd_dat{
			pins = <PINMUX_GPIO7__FUNC_GPIO7>;
			slew-rate = <1>;
			output-low;
			bias-disable;
		};
	};
};
/* eSE end */


/* haptic motor*/
&isa1000 {
	pinctrl-names = "default";
	pinctrl-0 = <&vibetonz_pwm>;
	isa1000_pdata {
		status = "okay";
		isa1000,max_timeout = <10000>;
		isa1000,ldo_type = <1>;
		isa1000,pwm_use = <1>;
		isa1000,duty = <35500>;
		isa1000,period = <37900>;
		isa1000,pwm_id = <0>;
		isa1000,gpio_en = <&expander_gpios0 11 0>;
	};
};

&pio {
	vibetonz_pwm: vibetonz_pwm {
		pins_cmd_dat {
			pins = <PINMUX_GPIO157__FUNC_DISP_PWM>;
			slew-rate = <1>;
			output-high;
		};
	};
};

&disp_pwm {
	clocks = <&infrasys INFRACFG_AO_DISP_PWM_CG>,
		<&topckgen TOP_MUX_DISP_PWM>;
	clock-names = "main", "mm";
};
